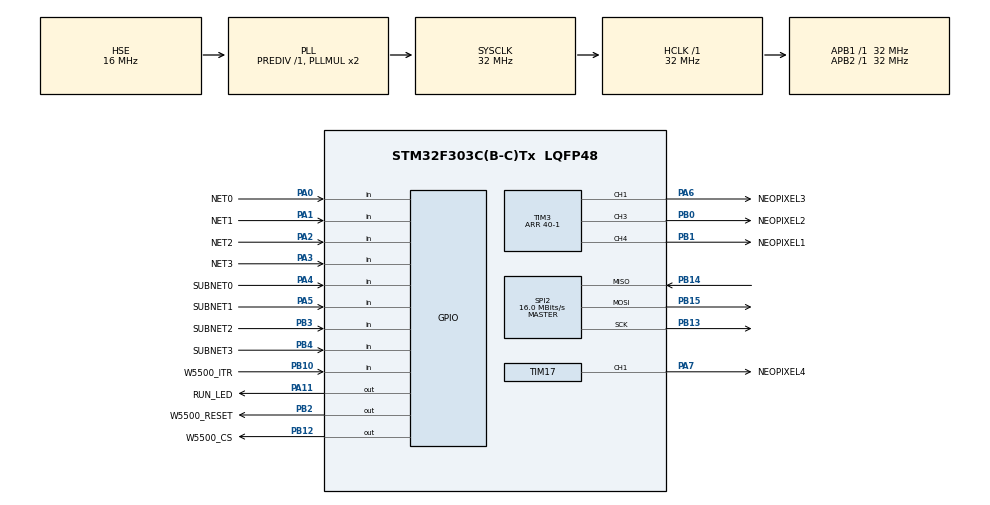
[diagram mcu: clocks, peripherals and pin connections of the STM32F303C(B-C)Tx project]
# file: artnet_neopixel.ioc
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Dma.Request0=TIM3_CH4/UP
Dma.Request1=TIM3_CH1/TRIG
Dma.Request2=TIM3_CH3
Dma.Request3=TIM17_CH1/UP
Dma.TIM17_CH1/UP.3.Direction=DMA_MEMORY_TO_PERIPH
Dma.TIM17_CH1/UP.3.Instance=DMA1_Channel1
Dma.TIM17_CH1/UP.3.MemDataAlignment=DMA_MDATAALIGN_BYTE
Dma.TIM17_CH1/UP.3.MemInc=DMA_MINC_ENABLE
Dma.TIM17_CH1/UP.3.Mode=DMA_NORMAL
Dma.TIM17_CH1/UP.3.PeriphDataAlignment=DMA_PDATAALIGN_HALFWORD
Dma.TIM17_CH1/UP.3.PeriphInc=DMA_PINC_DISABLE
Dma.TIM17_CH1/UP.3.Priority=DMA_PRIORITY_VERY_HIGH
Dma.TIM3_CH1/TRIG.1.Direction=DMA_MEMORY_TO_PERIPH
Dma.TIM3_CH1/TRIG.1.Instance=DMA1_Channel6
Dma.TIM3_CH1/TRIG.1.MemDataAlignment=DMA_MDATAALIGN_BYTE
Dma.TIM3_CH1/TRIG.1.MemInc=DMA_MINC_ENABLE
Dma.TIM3_CH1/TRIG.1.Mode=DMA_NORMAL
Dma.TIM3_CH1/TRIG.1.PeriphDataAlignment=DMA_PDATAALIGN_HALFWORD
Dma.TIM3_CH1/TRIG.1.PeriphInc=DMA_PINC_DISABLE
Dma.TIM3_CH1/TRIG.1.Priority=DMA_PRIORITY_VERY_HIGH
Dma.TIM3_CH3.2.Direction=DMA_MEMORY_TO_PERIPH
Dma.TIM3_CH3.2.Instance=DMA1_Channel2
Dma.TIM3_CH3.2.MemDataAlignment=DMA_MDATAALIGN_BYTE
Dma.TIM3_CH3.2.MemInc=DMA_MINC_ENABLE
Dma.TIM3_CH3.2.Mode=DMA_NORMAL
Dma.TIM3_CH3.2.PeriphDataAlignment=DMA_PDATAALIGN_HALFWORD
Dma.TIM3_CH3.2.PeriphInc=DMA_PINC_DISABLE
Dma.TIM3_CH3.2.Priority=DMA_PRIORITY_VERY_HIGH
Dma.TIM3_CH4/UP.0.Direction=DMA_MEMORY_TO_PERIPH
Dma.TIM3_CH4/UP.0.Instance=DMA1_Channel3
Dma.TIM3_CH4/UP.0.MemDataAlignment=DMA_MDATAALIGN_BYTE
Dma.TIM3_CH4/UP.0.MemInc=DMA_MINC_ENABLE
Dma.TIM3_CH4/UP.0.Mode=DMA_NORMAL
Dma.TIM3_CH4/UP.0.PeriphDataAlignment=DMA_PDATAALIGN_HALFWORD
Dma.TIM3_CH4/UP.0.PeriphInc=DMA_PINC_DISABLE
Dma.TIM3_CH4/UP.0.Priority=DMA_PRIORITY_VERY_HIGH
Mcu.Family=STM32F3
Mcu.Name=STM32F303C(B-C)Tx
Mcu.Package=LQFP48
NVIC.DMA1_Channel1_IRQn=true\:0\:0\:false\:false\:true\:false\:true\:true
NVIC.DMA1_Channel2_IRQn=true\:0\:0\:false\:false\:true\:false\:true\:true
NVIC.DMA1_Channel3_IRQn=true\:0\:0\:false\:false\:true\:false\:true\:true
NVIC.DMA1_Channel6_IRQn=true\:0\:0\:false\:false\:true\:false\:true\:true
NVIC.PriorityGroup=NVIC_PRIORITYGROUP_4
NVIC.TIM1_UP_TIM16_IRQn=true\:0\:0\:false\:false\:true\:true\:true\:true
NVIC.TIM7_IRQn=true\:0\:0\:false\:false\:true\:true\:true\:true
PA0.GPIO_Label=NET0
PA0.GPIO_PuPd=GPIO_PULLUP
PA0.Signal=GPIO_Input
PA1.GPIO_Label=NET1
PA1.GPIO_PuPd=GPIO_PULLUP
PA1.Signal=GPIO_Input
PA11.GPIO_Label=RUN_LED
PA11.Signal=GPIO_Output
PA13.Mode=Serial_Wire
PA13.Signal=SYS_JTMS-SWDIO
PA14.Mode=Serial_Wire
PA14.Signal=SYS_JTCK-SWCLK
PA2.GPIO_Label=NET2
PA2.GPIO_PuPd=GPIO_PULLUP
PA2.Signal=GPIO_Input
PA3.GPIO_Label=NET3
PA3.GPIO_PuPd=GPIO_PULLUP
PA3.Signal=GPIO_Input
PA4.GPIO_Label=SUBNET0
PA4.GPIO_PuPd=GPIO_PULLUP
PA4.Signal=GPIO_Input
PA5.GPIO_Label=SUBNET1
PA5.GPIO_PuPd=GPIO_PULLUP
PA5.Signal=GPIO_Input
PA6.GPIO_Label=NEOPIXEL3
PA6.GPIO_Speed=GPIO_SPEED_FREQ_HIGH
PA6.Signal=S_TIM3_CH1
PA7.GPIO_Label=NEOPIXEL4
PA7.GPIO_Speed=GPIO_SPEED_FREQ_HIGH
PA7.Signal=S_TIM17_CH1
PB0.GPIO_Label=NEOPIXEL2
PB0.GPIO_PuPd=GPIO_NOPULL
PB0.GPIO_Speed=GPIO_SPEED_FREQ_HIGH
PB0.Signal=S_TIM3_CH3
PB1.GPIO_Label=NEOPIXEL1
PB1.GPIO_Speed=GPIO_SPEED_FREQ_HIGH
PB1.Signal=S_TIM3_CH4
PB10.GPIO_Label=W5500_ITR
PB10.Signal=GPIO_Input
PB12.GPIO_Label=W5500_CS
PB12.Signal=GPIO_Output
PB13.Mode=Full_Duplex_Master
PB13.Signal=SPI2_SCK
PB14.Mode=Full_Duplex_Master
PB14.Signal=SPI2_MISO
PB15.Mode=Full_Duplex_Master
PB15.Signal=SPI2_MOSI
PB2.GPIO_Label=W5500_RESET
PB2.Signal=GPIO_Output
PB3.GPIO_Label=SUBNET2
PB3.GPIO_PuPd=GPIO_PULLUP
PB3.Signal=GPIO_Input
PB4.GPIO_Label=SUBNET3
PB4.GPIO_PuPd=GPIO_PULLUP
PB4.Signal=GPIO_Input
PF0-OSC_IN.Mode=HSE-External-Oscillator
PF0-OSC_IN.Signal=RCC_OSC_IN
PF1-OSC_OUT.Mode=HSE-External-Oscillator
PF1-OSC_OUT.Signal=RCC_OSC_OUT
ProjectManager.HeapSize=0x200
ProjectManager.StackSize=0x400
ProjectManager.TargetToolchain=Makefile
RCC.AHBFreq_Value=32000000
RCC.APB1Freq_Value=32000000
RCC.APB1TimFreq_Value=32000000
RCC.APB2Freq_Value=32000000
RCC.APB2TimFreq_Value=32000000
RCC.CortexFreq_Value=32000000
RCC.HCLKFreq_Value=32000000
RCC.HSE_VALUE=16000000
RCC.HSI_VALUE=8000000
RCC.LSE_VALUE=32768
RCC.PLLSourceVirtual=RCC_PLLSOURCE_HSE
RCC.SYSCLKFreq_VALUE=32000000
RCC.SYSCLKSourceVirtual=RCC_SYSCLKSOURCE_PLLCLK
RCC.USBFreq_Value=32000000
SH.S_TIM17_CH1.0=TIM17_CH1,PWM Generation1 CH1
SH.S_TIM3_CH1.0=TIM3_CH1,PWM Generation1 CH1
SH.S_TIM3_CH3.0=TIM3_CH3,PWM Generation3 CH3
SH.S_TIM3_CH4.0=TIM3_CH4,PWM Generation4 CH4
SPI2.BaudRatePrescaler=SPI_BAUDRATEPRESCALER_2
SPI2.CalculateBaudRate=16.0 MBits/s
SPI2.DataSize=SPI_DATASIZE_8BIT
SPI2.Direction=SPI_DIRECTION_2LINES
SPI2.Mode=SPI_MODE_MASTER
SPI2.VirtualType=VM_MASTER
TIM16.Period=40-1
TIM16.Prescaler=3200-1
TIM17.AutoReloadPreload=TIM_AUTORELOAD_PRELOAD_ENABLE
TIM17.Channel=TIM_CHANNEL_1
TIM17.Period=40-1
TIM3.AutoReloadPreload=TIM_AUTORELOAD_PRELOAD_ENABLE
TIM3.Channel-PWM\ Generation1\ CH1=TIM_CHANNEL_1
TIM3.Channel-PWM\ Generation3\ CH3=TIM_CHANNEL_3
TIM3.Channel-PWM\ Generation4\ CH4=TIM_CHANNEL_4
TIM3.OC1Preload_PWM=ENABLE
TIM3.OC3Preload_PWM=ENABLE
TIM3.OC4Preload_PWM=ENABLE
TIM3.OCFastMode_PWM-PWM\ Generation4\ CH4=TIM_OCFAST_DISABLE
TIM3.Period=40-1
TIM7.AutoReloadPreload=TIM_AUTORELOAD_PRELOAD_ENABLE
TIM7.Period=2500-1
TIM7.Prescaler=1600-1
VP_TIM16_VS_ClockSourceINT.Mode=Enable_Timer
VP_TIM17_VS_ClockSourceINT.Mode=Enable_Timer
VP_TIM3_VS_ClockSourceINT.Mode=Internal
VP_TIM7_VS_ClockSourceINT.Mode=Enable_Timer
board=custom

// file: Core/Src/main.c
/* USER CODE BEGIN Header */
/**
  ******************************************************************************
  * @file           : main.c
  * @brief          : Main program body
  ******************************************************************************
  * @attention
  *
  * Copyright (c) 2024 STMicroelectronics.
  * All rights reserved.
  *
  * This software is licensed under terms that can be found in the LICENSE file
  * in the root directory of this software component.
  * If no LICENSE file comes with this software, it is provided AS-IS.
  *
  ******************************************************************************
  */
/* USER CODE END Header */
#include "main.h"
#include "dma.h"
#include "spi.h"
#include "tim.h"
#include "gpio.h"

/* USER CODE BEGIN Includes */
#include "app.h"
/* USER CODE END Includes */

void SystemClock_Config(void);

int main(void)
{

  /* MCU Configuration--------------------------------------------------------*/

  /* Reset of all peripherals, Initializes the Flash interface and the Systick. */
  HAL_Init();

  /* Configure the system clock */
  SystemClock_Config();

  /* Initialize all configured peripherals */
  MX_GPIO_Init();
  MX_DMA_Init();
  MX_SPI2_Init();
  MX_TIM3_Init();
  MX_TIM17_Init();
  MX_TIM7_Init();
  MX_TIM16_Init();
  /* USER CODE BEGIN 2 */
  InitApp();
  /* USER CODE END 2 */

  /* Infinite loop */
  /* USER CODE BEGIN WHILE */
  while (1)
  {
    MainApp();
    /* USER CODE END WHILE */

  }
}

void SystemClock_Config(void)
{
  RCC_OscInitTypeDef RCC_OscInitStruct = {0};
  RCC_ClkInitTypeDef RCC_ClkInitStruct = {0};

  /** Initializes the RCC Oscillators according to the specified parameters
  * in the RCC_OscInitTypeDef structure.
  */
  RCC_OscInitStruct.OscillatorType = RCC_OSCILLATORTYPE_HSE;
  RCC_OscInitStruct.HSEState = RCC_HSE_ON;
  RCC_OscInitStruct.HSEPredivValue = RCC_HSE_PREDIV_DIV1;
  RCC_OscInitStruct.HSIState = RCC_HSI_ON;
  RCC_OscInitStruct.PLL.PLLState = RCC_PLL_ON;
  RCC_OscInitStruct.PLL.PLLSource = RCC_PLLSOURCE_HSE;
  RCC_OscInitStruct.PLL.PLLMUL = RCC_PLL_MUL2;
  if (HAL_RCC_OscConfig(&RCC_OscInitStruct) != HAL_OK)
  {
    Error_Handler();
  }

  /** Initializes the CPU, AHB and APB buses clocks
  */
  RCC_ClkInitStruct.ClockType = RCC_CLOCKTYPE_HCLK|RCC_CLOCKTYPE_SYSCLK
                              |RCC_CLOCKTYPE_PCLK1|RCC_CLOCKTYPE_PCLK2;
  RCC_ClkInitStruct.SYSCLKSource = RCC_SYSCLKSOURCE_PLLCLK;
  RCC_ClkInitStruct.AHBCLKDivider = RCC_SYSCLK_DIV1;
  RCC_ClkInitStruct.APB1CLKDivider = RCC_HCLK_DIV1;
  RCC_ClkInitStruct.APB2CLKDivider = RCC_HCLK_DIV1;

  if (HAL_RCC_ClockConfig(&RCC_ClkInitStruct, FLASH_LATENCY_1) != HAL_OK)
  {
    Error_Handler();
  }
}

void Error_Handler(void)
{
  __disable_irq();
  while (1)
  {
  }
}
